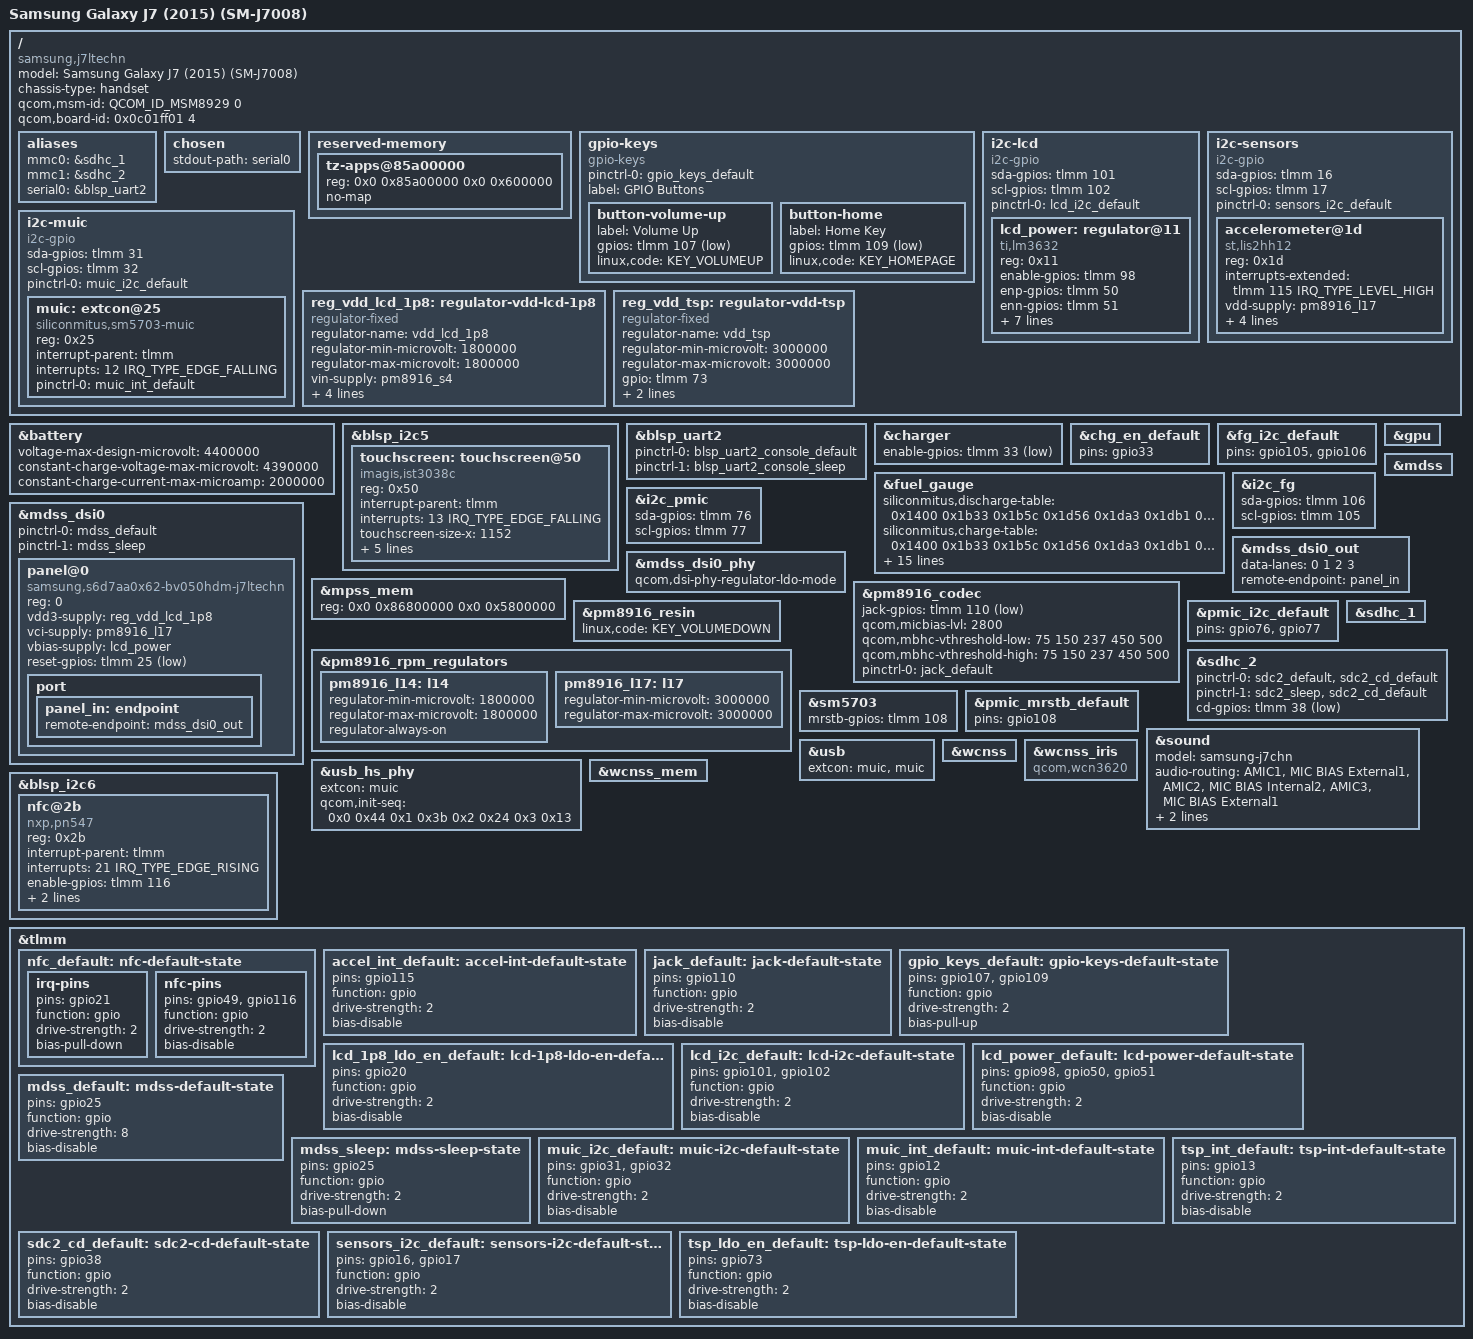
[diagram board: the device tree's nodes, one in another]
// SPDX-License-Identifier: GPL-2.0-only

/dts-v1/;

#include "msm8929-pm8916.dtsi"
#include "msm8916-modem-qdsp6.dtsi"
#include "msm8916-samsung-sm5703.dtsi"

#include <dt-bindings/arm/qcom,ids.h>
#include <dt-bindings/gpio/gpio.h>
#include <dt-bindings/input/input.h>
#include <dt-bindings/interrupt-controller/irq.h>

/ {
	model = "Samsung Galaxy J7 (2015) (SM-J7008)";
	compatible = "samsung,j7ltechn", "qcom,msm8929";
	chassis-type = "handset";

	qcom,msm-id = <QCOM_ID_MSM8929 0>;
	qcom,board-id = <0x0c01ff01 4>;

	aliases {
		mmc0 = &sdhc_1; /* eMMC */
		mmc1 = &sdhc_2; /* SD card */
		serial0 = &blsp_uart2;
	};

	chosen {
		stdout-path = "serial0";
	};

	reserved-memory {
		/* Additional memory used by Samsung firmware modifications */
		tz-apps@85a00000 {
			reg = <0x0 0x85a00000 0x0 0x600000>;
			no-map;
		};
	};

	gpio-keys {
		compatible = "gpio-keys";

		pinctrl-0 = <&gpio_keys_default>;
		pinctrl-names = "default";

		label = "GPIO Buttons";

		button-volume-up {
			label = "Volume Up";
			gpios = <&tlmm 107 GPIO_ACTIVE_LOW>;
			linux,code = <KEY_VOLUMEUP>;
		};

		button-home {
			label = "Home Key";
			gpios = <&tlmm 109 GPIO_ACTIVE_LOW>;
			linux,code = <KEY_HOMEPAGE>;
		};
	};

	i2c-lcd {
		compatible = "i2c-gpio";
		sda-gpios = <&tlmm 101 (GPIO_ACTIVE_HIGH|GPIO_OPEN_DRAIN)>;
		scl-gpios = <&tlmm 102 (GPIO_ACTIVE_HIGH|GPIO_OPEN_DRAIN)>;

		pinctrl-0 = <&lcd_i2c_default>;
		pinctrl-names = "default";

		#address-cells = <1>;
		#size-cells = <0>;

		lcd_power: regulator@11 {
			compatible = "ti,lm3632";
			reg = <0x11>;

			enable-gpios = <&tlmm 98 GPIO_ACTIVE_HIGH>;
			enp-gpios = <&tlmm 50 GPIO_ACTIVE_HIGH>;
			enn-gpios = <&tlmm 51 GPIO_ACTIVE_HIGH>;

			ti,init-sequence = /bits/ 8 <
				0x09 0x41
				0x02 0x50
				0x03 0x0d
				0x04 0x05
				0x0a 0x19
				0x05 0xcc
				0x0d 0x1e
				0x0e 0x1e
				0x0f 0x1e
				0x0c 0x1f
			>;

			pinctrl-0 = <&lcd_power_default>;
			pinctrl-names = "default";

			regulator-name = "lcd_power";
			regulator-min-microvolt = <5500000>;
			regulator-max-microvolt = <5500000>;
			regulator-boot-on;
		};
	};

	i2c-muic {
		compatible = "i2c-gpio";
		sda-gpios = <&tlmm 31 (GPIO_ACTIVE_HIGH|GPIO_OPEN_DRAIN)>;
		scl-gpios = <&tlmm 32 (GPIO_ACTIVE_HIGH|GPIO_OPEN_DRAIN)>;

		pinctrl-0 = <&muic_i2c_default>;
		pinctrl-names = "default";

		#address-cells = <1>;
		#size-cells = <0>;

		muic: extcon@25 {
			compatible = "siliconmitus,sm5703-muic";
			reg = <0x25>;

			interrupt-parent = <&tlmm>;
			interrupts = <12 IRQ_TYPE_EDGE_FALLING>;

			pinctrl-0 = <&muic_int_default>;
			pinctrl-names = "default";
		};
	};

	i2c-sensors {
		compatible = "i2c-gpio";
		sda-gpios = <&tlmm 16 (GPIO_ACTIVE_HIGH|GPIO_OPEN_DRAIN)>;
		scl-gpios = <&tlmm 17 (GPIO_ACTIVE_HIGH|GPIO_OPEN_DRAIN)>;

		pinctrl-0 = <&sensors_i2c_default>;
		pinctrl-names = "default";

		#address-cells = <1>;
		#size-cells = <0>;

		accelerometer@1d {
			compatible = "st,lis2hh12";
			reg = <0x1d>;

			interrupts-extended = <&tlmm 115 IRQ_TYPE_LEVEL_HIGH>;

			vdd-supply = <&pm8916_l17>;
			vddio-supply = <&pm8916_l5>;

			pinctrl-0 = <&accel_int_default>;
			pinctrl-names = "default";

			st,drdy-int-pin = <1>;

			mount-matrix = "-1", "0", "0",
				       "0", "-1", "0",
				       "0", "0", "1";
		};
	};

	reg_vdd_lcd_1p8: regulator-vdd-lcd-1p8 {
		compatible = "regulator-fixed";
		regulator-name = "vdd_lcd_1p8";
		regulator-min-microvolt = <1800000>;
		regulator-max-microvolt = <1800000>;
		vin-supply = <&pm8916_s4>;

		gpio = <&tlmm 20 GPIO_ACTIVE_HIGH>;
		enable-active-high;

		/* Keep the display powered until the panel driver takes over */
		regulator-boot-on;

		pinctrl-0 = <&lcd_1p8_ldo_en_default>;
		pinctrl-names = "default";
	};

	reg_vdd_tsp: regulator-vdd-tsp {
		compatible = "regulator-fixed";
		regulator-name = "vdd_tsp";
		regulator-min-microvolt = <3000000>;
		regulator-max-microvolt = <3000000>;

		gpio = <&tlmm 73 GPIO_ACTIVE_HIGH>;
		enable-active-high;

		pinctrl-0 = <&tsp_ldo_en_default>;
		pinctrl-names = "default";
	};
};

&battery {
	voltage-max-design-microvolt = <4400000>;
	constant-charge-voltage-max-microvolt = <4390000>;
	constant-charge-current-max-microamp = <2000000>;
};

&blsp_i2c5 {
	status = "okay";

	touchscreen: touchscreen@50 {
		compatible = "imagis,ist3038c";
		reg = <0x50>;

		interrupt-parent = <&tlmm>;
		interrupts = <13 IRQ_TYPE_EDGE_FALLING>;

		touchscreen-size-x = <1152>;
		touchscreen-size-y = <2047>;

		linux,keycodes = <KEY_APPSELECT>, <KEY_BACK>;

		vdd-supply = <&reg_vdd_tsp>;
		vddio-supply = <&pm8916_l6>;

		pinctrl-0 = <&tsp_int_default>;
		pinctrl-names = "default";
	};
};

&blsp_uart2 {
	pinctrl-0 = <&blsp_uart2_console_default>;
	pinctrl-1 = <&blsp_uart2_console_sleep>;
	pinctrl-names = "default", "sleep";
	status = "okay";
};

&charger {
	enable-gpios = <&tlmm 33 GPIO_ACTIVE_LOW>;
};

&chg_en_default {
	pins = "gpio33";
};

&fg_i2c_default {
	pins = "gpio105", "gpio106";
};

&fuel_gauge {
	siliconmitus,discharge-table = <0x1400 0x1b33 0x1b5c 0x1d56
					0x1da3 0x1db1 0x1e1d 0x1e4a
					0x1e8e 0x1efd 0x1f28 0x1f93
					0x2035 0x20fd 0x22e1 0x2431>;
	siliconmitus,charge-table = <0x1400 0x1b33 0x1b5c 0x1d56
				     0x1da3 0x1db1 0x1e1d 0x1e4a
				     0x1e8e 0x1efd 0x1f28 0x1f93
				     0x2035 0x20fd 0x22e1 0x2431>;
	siliconmitus,q-table = <0x0000 0x0006 0x003d 0x0133
				0x01cd 0x0300 0x04cd 0x0600
				0x0999 0x0c99 0x0d33 0x0e66
				0x10cc 0x1333 0x1800 0x1806>;
	siliconmitus,rce = <0x0749 0x0580 0x0371>;
	siliconmitus,rs = <0x01ae 0x047a 0x3800 0x00a4>;
	siliconmitus,mix = <0x0a03 0x0004>;
	siliconmitus,topoff-soc = <0 5>;
	siliconmitus,dtcd = <1>;
	siliconmitus,vit-period = <0x350a>;
	siliconmitus,volt-cal = <0x8000>;
	siliconmitus,curr-cal = <0x7500>;
	siliconmitus,temp-offset-cal = <1>;
	siliconmitus,charge-offset-cal = <0>;
	siliconmitus,temp-poff = <3420 100 3350 100>;
	siliconmitus,ext-temp-cal = <1 10 1 1 1 7 2 2>;
	siliconmitus,min-charge-current-milliamp = <100>;
};

&gpu {
	status = "okay";
};

&i2c_fg {
	sda-gpios = <&tlmm 106 (GPIO_ACTIVE_HIGH|GPIO_OPEN_DRAIN)>;
	scl-gpios = <&tlmm 105 (GPIO_ACTIVE_HIGH|GPIO_OPEN_DRAIN)>;
};

&i2c_pmic {
	sda-gpios = <&tlmm 76 (GPIO_ACTIVE_HIGH|GPIO_OPEN_DRAIN)>;
	scl-gpios = <&tlmm 77 (GPIO_ACTIVE_HIGH|GPIO_OPEN_DRAIN)>;
};

&mdss {
	status = "okay";
};

&mdss_dsi0 {
	pinctrl-0 = <&mdss_default>;
	pinctrl-1 = <&mdss_sleep>;
	pinctrl-names = "default", "sleep";

	status = "okay";

	panel@0 {
		compatible = "samsung,s6d7aa0x62-bv050hdm-j7ltechn";
		reg = <0>;

		vdd3-supply = <&reg_vdd_lcd_1p8>;
		vci-supply = <&pm8916_l17>;
		vbias-supply = <&lcd_power>;

		reset-gpios = <&tlmm 25 GPIO_ACTIVE_LOW>;

		port {
			panel_in: endpoint {
				remote-endpoint = <&mdss_dsi0_out>;
			};
		};
	};
};

&mdss_dsi0_out {
	data-lanes = <0 1 2 3>;
	remote-endpoint = <&panel_in>;
};

&mdss_dsi0_phy {
	qcom,dsi-phy-regulator-ldo-mode;
	status = "okay";
};

&mpss_mem {
	reg = <0x0 0x86800000 0x0 0x5800000>;
};

&pm8916_codec {
	jack-gpios = <&tlmm 110 GPIO_ACTIVE_LOW>;
	qcom,micbias-lvl = <2800>;
	qcom,mbhc-vthreshold-low = <75 150 237 450 500>;
	qcom,mbhc-vthreshold-high = <75 150 237 450 500>;

	pinctrl-0 = <&jack_default>;
	pinctrl-names = "default";
};

&pm8916_resin {
	linux,code = <KEY_VOLUMEDOWN>;
	status = "okay";
};

&pm8916_rpm_regulators {
	pm8916_l14: l14 {
		regulator-min-microvolt = <1800000>;
		regulator-max-microvolt = <1800000>;
		regulator-always-on;
	};

	pm8916_l17: l17 {
		regulator-min-microvolt = <3000000>;
		regulator-max-microvolt = <3000000>;
	};
};

&pmic_i2c_default {
	pins = "gpio76", "gpio77";
};

&sdhc_1 {
	status = "okay";
};

&sdhc_2 {
	pinctrl-0 = <&sdc2_default &sdc2_cd_default>;
	pinctrl-1 = <&sdc2_sleep &sdc2_cd_default>;
	pinctrl-names = "default", "sleep";

	cd-gpios = <&tlmm 38 GPIO_ACTIVE_LOW>;

	status = "okay";
};

&sm5703 {
	mrstb-gpios = <&tlmm 108 GPIO_ACTIVE_HIGH>;
};

&pmic_mrstb_default {
	pins = "gpio108";
};

&sound {
	model = "samsung-j7chn";
	audio-routing =
		"AMIC1", "MIC BIAS External1",
		"AMIC2", "MIC BIAS Internal2",
		"AMIC3", "MIC BIAS External1";

	pinctrl-0 = <&cdc_pdm_default>;
	pinctrl-1 = <&cdc_pdm_sleep>;
	pinctrl-names = "default", "sleep";
};

&usb {
	extcon = <&muic>, <&muic>;
	status = "okay";
};

&usb_hs_phy {
	extcon = <&muic>;
	qcom,init-seq = /bits/ 8 <0x0 0x44 0x1 0x3b 0x2 0x24 0x3 0x13>;
};

&wcnss {
	status = "okay";
};

&wcnss_iris {
	compatible = "qcom,wcn3620";
};

&wcnss_mem {
	status = "okay";
};

&blsp_i2c6 {
	status = "okay";

	nfc@2b {
		compatible = "nxp,pn547", "nxp,nxp-nci-i2c";
		reg = <0x2b>;

		interrupt-parent = <&tlmm>;
		interrupts = <21 IRQ_TYPE_EDGE_RISING>;

		enable-gpios = <&tlmm 116 GPIO_ACTIVE_HIGH>;
		firmware-gpios = <&tlmm 49 GPIO_ACTIVE_HIGH>;

		pinctrl-0 = <&nfc_default>;
		pinctrl-names = "default";
	};
};

&tlmm {
	nfc_default: nfc-default-state {
		irq-pins {
			pins = "gpio21";
			function = "gpio";
			drive-strength = <2>;
			bias-pull-down;
		};

		nfc-pins {
			pins = "gpio49", "gpio116";
			function = "gpio";
			drive-strength = <2>;
			bias-disable;
		};
	};

	accel_int_default: accel-int-default-state {
		pins = "gpio115";
		function = "gpio";
		drive-strength = <2>;
		bias-disable;
	};

	jack_default: jack-default-state {
		pins = "gpio110";
		function = "gpio";
		drive-strength = <2>;
		bias-disable;
	};

	gpio_keys_default: gpio-keys-default-state {
		pins = "gpio107", "gpio109";
		function = "gpio";
		drive-strength = <2>;
		bias-pull-up;
	};

	lcd_1p8_ldo_en_default: lcd-1p8-ldo-en-default-state {
		pins = "gpio20";
		function = "gpio";
		drive-strength = <2>;
		bias-disable;
	};

	lcd_i2c_default: lcd-i2c-default-state {
		pins = "gpio101", "gpio102";
		function = "gpio";
		drive-strength = <2>;
		bias-disable;
	};

	lcd_power_default: lcd-power-default-state {
		pins = "gpio98", "gpio50", "gpio51";
		function = "gpio";
		drive-strength = <2>;
		bias-disable;
	};

	mdss_default: mdss-default-state {
		pins = "gpio25";
		function = "gpio";
		drive-strength = <8>;
		bias-disable;
	};

	mdss_sleep: mdss-sleep-state {
		pins = "gpio25";
		function = "gpio";
		drive-strength = <2>;
		bias-pull-down;
	};

	muic_i2c_default: muic-i2c-default-state {
		pins = "gpio31", "gpio32";
		function = "gpio";
		drive-strength = <2>;
		bias-disable;
	};

	muic_int_default: muic-int-default-state {
		pins = "gpio12";
		function = "gpio";
		drive-strength = <2>;
		bias-disable;
	};

	sdc2_cd_default: sdc2-cd-default-state {
		pins = "gpio38";
		function = "gpio";
		drive-strength = <2>;
		bias-disable;
	};

	sensors_i2c_default: sensors-i2c-default-state {
		pins = "gpio16", "gpio17";
		function = "gpio";
		drive-strength = <2>;
		bias-disable;
	};

	tsp_int_default: tsp-int-default-state {
		pins = "gpio13";
		function = "gpio";
		drive-strength = <2>;
		bias-disable;
	};

	tsp_ldo_en_default: tsp-ldo-en-default-state {
		pins = "gpio73";
		function = "gpio";
		drive-strength = <2>;
		bias-disable;
	};
};
